AUTOSAR XML (schema 4-2-2)
package /ComponentTypes
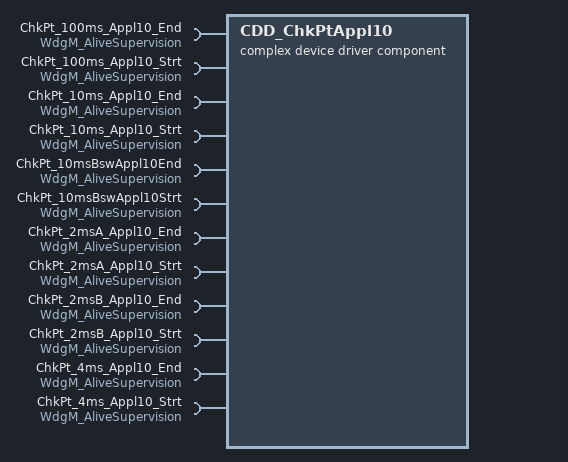
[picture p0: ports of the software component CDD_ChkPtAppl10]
  complex device driver sw component type CDD_ChkPtAppl10
    12 x require port, all with client-com-spec=CheckpointReached, required-interface=WdgM_AliveSupervision:
      ChkPt_100ms_Appl10_End
      ChkPt_100ms_Appl10_Strt
      ChkPt_10ms_Appl10_End
      ChkPt_10ms_Appl10_Strt
      ChkPt_10msBswAppl10End
      ChkPt_10msBswAppl10Strt
      ChkPt_2msA_Appl10_End
      ChkPt_2msA_Appl10_Strt
      ChkPt_2msB_Appl10_End
      ChkPt_2msB_Appl10_Strt
      ChkPt_4ms_Appl10_End
      ChkPt_4ms_Appl10_Strt
    behavior CDD_ChkPtAppl10_InternalBehavior
      10 x timing event:
        TMT_ChkPt_100msAppl10End: start-on-event=ChkPt_100msAppl10End, period=0.1
        TMT_ChkPt_100msAppl10Strt: start-on-event=ChkPt_100msAppl10Strt, period=0.1
        TMT_ChkPt_10msAppl10End: start-on-event=ChkPt_10msAppl10End, period=0.01
        TMT_ChkPt_10msAppl10Strt: start-on-event=ChkPt_10msAppl10Strt, period=0.01
        TMT_ChkPt_2msAAppl10End: start-on-event=ChkPt_2msAAppl10End, period=0.002
        TMT_ChkPt_2msAAppl10Strt: start-on-event=ChkPt_2msAAppl10Strt, period=0.002
        TMT_ChkPt_2msBAppl10End: start-on-event=ChkPt_2msBAppl10End, period=0.002
        TMT_ChkPt_2msBAppl10Strt: start-on-event=ChkPt_2msBAppl10Strt, period=0.002
        TMT_ChkPt_4msAppl10End: start-on-event=ChkPt_4msAppl10End, period=0.004
        TMT_ChkPt_4msAppl10Strt: start-on-event=ChkPt_4msAppl10Strt, period=0.004
      port-api-options:
        enable-take-address=false, error-handling=NO-TRANSFORMER-ERROR-HANDLING, indirect-api=false, port=ChkPt_100ms_Appl10_End
        enable-take-address=false, error-handling=NO-TRANSFORMER-ERROR-HANDLING, indirect-api=false, port=ChkPt_100ms_Appl10_Strt
        enable-take-address=false, error-handling=NO-TRANSFORMER-ERROR-HANDLING, indirect-api=false, port=ChkPt_10ms_Appl10_End
        enable-take-address=false, error-handling=NO-TRANSFORMER-ERROR-HANDLING, indirect-api=false, port=ChkPt_10ms_Appl10_Strt
        enable-take-address=false, error-handling=NO-TRANSFORMER-ERROR-HANDLING, indirect-api=false, port=ChkPt_10msBswAppl10End
        enable-take-address=false, error-handling=NO-TRANSFORMER-ERROR-HANDLING, indirect-api=false, port=ChkPt_10msBswAppl10Strt
        enable-take-address=false, error-handling=NO-TRANSFORMER-ERROR-HANDLING, indirect-api=false, port=ChkPt_2msA_Appl10_End
        enable-take-address=false, error-handling=NO-TRANSFORMER-ERROR-HANDLING, indirect-api=false, port=ChkPt_2msA_Appl10_Strt
        enable-take-address=false, error-handling=NO-TRANSFORMER-ERROR-HANDLING, indirect-api=false, port=ChkPt_2msB_Appl10_End
        enable-take-address=false, error-handling=NO-TRANSFORMER-ERROR-HANDLING, indirect-api=false, port=ChkPt_2msB_Appl10_Strt
        enable-take-address=false, error-handling=NO-TRANSFORMER-ERROR-HANDLING, indirect-api=false, port=ChkPt_4ms_Appl10_End
        enable-take-address=false, error-handling=NO-TRANSFORMER-ERROR-HANDLING, indirect-api=false, port=ChkPt_4ms_Appl10_Strt
      10 x runnable:
        ChkPt_100msAppl10End
          sync call SC_ChkPt_100ms_Appl10_End_CheckpointReached: operation=ChkPt_100ms_Appl10_End.CheckpointReached, timeout=0
        ChkPt_100msAppl10Strt
          sync call SC_ChkPt_100ms_Appl10_Strt_CheckpointReached: operation=ChkPt_100ms_Appl10_Strt.CheckpointReached, timeout=0
        ChkPt_10msAppl10End
          sync call SC_ChkPt_10ms_Appl10_End_CheckpointReached: operation=ChkPt_10ms_Appl10_End.CheckpointReached, timeout=0
        ChkPt_10msAppl10Strt
          sync call SC_ChkPt_10ms_Appl10_Strt_CheckpointReached: operation=ChkPt_10ms_Appl10_Strt.CheckpointReached, timeout=0
        ChkPt_2msAAppl10End
          sync call SC_ChkPt_2msA_Appl10_End_CheckpointReached: operation=ChkPt_2msA_Appl10_End.CheckpointReached, timeout=0
        ChkPt_2msAAppl10Strt
          sync call SC_ChkPt_2msA_Appl10_Strt_CheckpointReached: operation=ChkPt_2msA_Appl10_Strt.CheckpointReached, timeout=0
        ChkPt_2msBAppl10End
          sync call SC_ChkPt_2msB_Appl10_End_CheckpointReached: operation=ChkPt_2msB_Appl10_End.CheckpointReached, timeout=0
        ChkPt_2msBAppl10Strt
          sync call SC_ChkPt_2msB_Appl10_Strt_CheckpointReached: operation=ChkPt_2msB_Appl10_Strt.CheckpointReached, timeout=0
        ChkPt_4msAppl10End
          sync call SC_ChkPt_4ms_Appl10_End_CheckpointReached: operation=ChkPt_4ms_Appl10_End.CheckpointReached, timeout=0
        ChkPt_4msAppl10Strt
          sync call SC_ChkPt_4ms_Appl10_Strt_CheckpointReached: operation=ChkPt_4ms_Appl10_Strt.CheckpointReached, timeout=0
  swc implementation CDD_ChkPtAppl10_Implementation: behavior=CDD_ChkPtAppl10_InternalBehavior
    code-descriptors:
      code Default: artifact-descriptors=autosar-engineering-object={short-label=Default, category=SWSRC}
